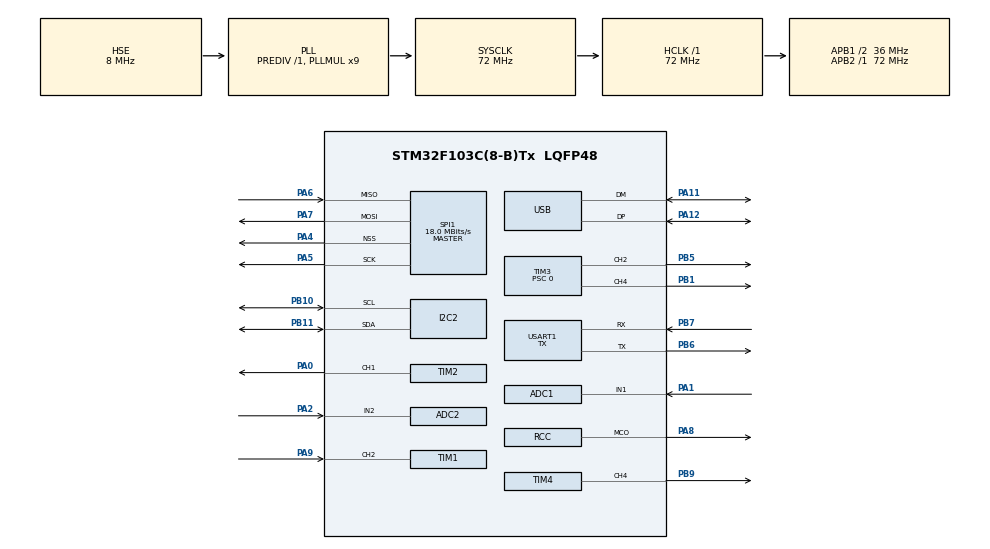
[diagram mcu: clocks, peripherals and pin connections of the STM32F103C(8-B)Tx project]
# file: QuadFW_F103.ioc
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ADC1.Channel-24\#ChannelRegularConversion=ADC_CHANNEL_1
ADC1.NbrOfConversionFlag=1
ADC1.Rank-24\#ChannelRegularConversion=1
ADC1.SamplingTime-24\#ChannelRegularConversion=ADC_SAMPLETIME_1CYCLE_5
ADC1.master=1
ADC2.Channel-18\#ChannelRegularConversion=ADC_CHANNEL_2
ADC2.NbrOfConversionFlag=1
ADC2.Rank-18\#ChannelRegularConversion=1
ADC2.SamplingTime-18\#ChannelRegularConversion=ADC_SAMPLETIME_1CYCLE_5
Dma.Request0=USART1_TX
Dma.USART1_TX.0.Direction=DMA_MEMORY_TO_PERIPH
Dma.USART1_TX.0.Instance=DMA1_Channel4
Dma.USART1_TX.0.MemDataAlignment=DMA_MDATAALIGN_BYTE
Dma.USART1_TX.0.MemInc=DMA_MINC_ENABLE
Dma.USART1_TX.0.Mode=DMA_NORMAL
Dma.USART1_TX.0.PeriphDataAlignment=DMA_PDATAALIGN_BYTE
Dma.USART1_TX.0.PeriphInc=DMA_PINC_DISABLE
Dma.USART1_TX.0.Priority=DMA_PRIORITY_LOW
FREERTOS.BinarySemaphores01=loggerLock,Dynamic,NULL
FREERTOS.INCLUDE_uxTaskPriorityGet=0
FREERTOS.INCLUDE_vTaskDelete=0
FREERTOS.INCLUDE_vTaskPrioritySet=0
FREERTOS.INCLUDE_vTaskSuspend=0
FREERTOS.INCLUDE_xTaskResumeFromISR=0
FREERTOS.Tasks01=systemLoggerTask,-1,512,SystemLoggerTask,As weak,NULL,Dynamic,NULL,NULL;systemCoreTask,3,128,SystemCoreTask,As external,NULL,Dynamic,NULL,NULL
FREERTOS.Timers01=controlTimer,ControlEvent,osTimerPeriodic,As external,NULL,Dynamic,NULL;positionUpdateTimer,PositionUpdateEvent,osTimerPeriodic,As external,NULL,Dynamic,NULL;sendLogTimer,SendLogEvent,osTimerPeriodic,As external,NULL,Dynamic,NULL
FREERTOS.configCHECK_FOR_STACK_OVERFLOW=2
FREERTOS.configGENERATE_RUN_TIME_STATS=0
FREERTOS.configMAX_TASK_NAME_LEN=32
FREERTOS.configMINIMAL_STACK_SIZE=128
FREERTOS.configTIMER_QUEUE_LENGTH=20
FREERTOS.configTIMER_TASK_PRIORITY=6
FREERTOS.configTOTAL_HEAP_SIZE=10240
FREERTOS.configUSE_DAEMON_TASK_STARTUP_HOOK=1
FREERTOS.configUSE_TIMERS=1
FREERTOS.configUSE_TRACE_FACILITY=1
I2C2.I2C_Mode=I2C_Fast
Mcu.Family=STM32F1
Mcu.Name=STM32F103C(8-B)Tx
Mcu.Package=LQFP48
NVIC.DMA1_Channel4_IRQn=true\:5\:0\:false\:false\:true\:true\:false
NVIC.PriorityGroup=NVIC_PRIORITYGROUP_4
NVIC.TIM1_BRK_IRQn=true\:5\:0\:false\:false\:true\:true\:true
NVIC.TIM1_CC_IRQn=true\:5\:0\:false\:false\:true\:true\:true
NVIC.TIM1_TRG_COM_IRQn=true\:5\:0\:false\:false\:true\:true\:true
NVIC.TIM1_UP_IRQn=true\:5\:0\:false\:false\:true\:true\:true
NVIC.USART1_IRQn=true\:5\:0\:false\:false\:true\:true\:true
PA0-WKUP.Signal=S_TIM2_CH1_ETR
PA1.Signal=ADCx_IN1
PA11.Mode=Device
PA11.Signal=USB_DM
PA12.Mode=Device
PA12.Signal=USB_DP
PA13.Mode=Serial_Wire
PA13.Signal=SYS_JTMS-SWDIO
PA14.Mode=Serial_Wire
PA14.Signal=SYS_JTCK-SWCLK
PA2.Signal=ADCx_IN2
PA4.Mode=NSS_Signal_Hard_Output
PA4.Signal=SPI1_NSS
PA5.Mode=Full_Duplex_Master
PA5.Signal=SPI1_SCK
PA6.Mode=Full_Duplex_Master
PA6.Signal=SPI1_MISO
PA7.Mode=Full_Duplex_Master
PA7.Signal=SPI1_MOSI
PA8.Mode=Clock-out
PA8.Signal=RCC_MCO
PA9.Signal=S_TIM1_CH2
PB1.Signal=S_TIM3_CH4
PB10.Mode=I2C
PB10.Signal=I2C2_SCL
PB11.Mode=I2C
PB11.Signal=I2C2_SDA
PB5.Signal=S_TIM3_CH2
PB6.Mode=Asynchronous
PB6.Signal=USART1_TX
PB7.Mode=Asynchronous
PB7.Signal=USART1_RX
PB9.Signal=S_TIM4_CH4
PD0-OSC_IN.Mode=HSE-External-Oscillator
PD0-OSC_IN.Signal=RCC_OSC_IN
PD1-OSC_OUT.Mode=HSE-External-Oscillator
PD1-OSC_OUT.Signal=RCC_OSC_OUT
ProjectManager.HeapSize=0x200
ProjectManager.StackSize=0x400
ProjectManager.TargetToolchain=TrueSTUDIO
RCC.ADCPresc=RCC_ADCPCLK2_DIV6
RCC.AHBFreq_Value=72000000
RCC.APB1CLKDivider=RCC_HCLK_DIV2
RCC.APB1Freq_Value=36000000
RCC.APB1TimFreq_Value=72000000
RCC.APB2Freq_Value=72000000
RCC.APB2TimFreq_Value=72000000
RCC.HCLKFreq_Value=72000000
RCC.PLLMUL=RCC_PLL_MUL9
RCC.RCC_MCOSource=RCC_MCO1SOURCE_PLLCLK
RCC.SYSCLKFreq_VALUE=72000000
RCC.SYSCLKSource=RCC_SYSCLKSOURCE_PLLCLK
RCC.USBFreq_Value=48000000
RCC.USBPrescaler=RCC_USBCLKSOURCE_PLL_DIV1_5
SH.ADCx_IN1.0=ADC1_IN1,IN1
SH.ADCx_IN2.0=ADC2_IN2,IN2
SH.S_TIM1_CH2.0=TIM1_CH2,Input_Capture2_from_TI2
SH.S_TIM2_CH1_ETR.0=TIM2_CH1,PWM Generation1 CH1
SH.S_TIM3_CH2.0=TIM3_CH2,PWM Generation2 CH2
SH.S_TIM3_CH4.0=TIM3_CH4,PWM Generation4 CH4
SH.S_TIM4_CH4.0=TIM4_CH4,PWM Generation4 CH4
SPI1.BaudRatePrescaler=SPI_BAUDRATEPRESCALER_4
SPI1.CalculateBaudRate=18.0 MBits/s
SPI1.Direction=SPI_DIRECTION_2LINES
SPI1.Mode=SPI_MODE_MASTER
SPI1.VirtualNSS=VM_NSSHARD
SPI1.VirtualType=VM_MASTER
TIM1.Channel-Input_Capture2_from_TI2=TIM_CHANNEL_2
TIM1.Period=20000
TIM1.Prescaler=71
TIM2.Channel-PWM\ Generation1\ CH1=TIM_CHANNEL_1
TIM2.Period=1023
TIM2.Prescaler=0
TIM3.Channel-PWM\ Generation2\ CH2=TIM_CHANNEL_2
TIM3.Channel-PWM\ Generation4\ CH4=TIM_CHANNEL_4
TIM3.Period=1023
TIM3.Prescaler=0
TIM4.Channel-PWM\ Generation4\ CH4=TIM_CHANNEL_4
TIM4.Period=1023
TIM4.Prescaler=0
USART1.Mode=MODE_TX
USART1.VirtualMode=VM_ASYNC
VP_FREERTOS_VS_ENABLE.Mode=Enabled
board=custom

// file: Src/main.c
/* USER CODE BEGIN Header */
/**
  ******************************************************************************
  * @file           : main.c
  * @brief          : Main program body
  ******************************************************************************
  * This notice applies to any and all portions of this file
  * that are not between comment pairs USER CODE BEGIN and
  * USER CODE END. Other portions of this file, whether
  * inserted by the user or by software development tools
  * are owned by their respective copyright owners.
  *
  * Copyright (c) 2019 STMicroelectronics International N.V.
  * All rights reserved.
  *
  * Redistribution and use in source and binary forms, with or without
  * modification, are permitted, provided that the following conditions are met:
  *
  * 1. Redistribution of source code must retain the above copyright notice,
  *    this list of conditions and the following disclaimer.
  * 2. Redistributions in binary form must reproduce the above copyright notice,
  *    this list of conditions and the following disclaimer in the documentation
  *    and/or other materials provided with the distribution.
  * 3. Neither the name of STMicroelectronics nor the names of other
  *    contributors to this software may be used to endorse or promote products
  *    derived from this software without specific written permission.
  * 4. This software, including modifications and/or derivative works of this
  *    software, must execute solely and exclusively on microcontroller or
  *    microprocessor devices manufactured by or for STMicroelectronics.
  * 5. Redistribution and use of this software other than as permitted under
  *    this license is void and will automatically terminate your rights under
  *    this license.
  *
  * THIS SOFTWARE IS PROVIDED BY STMICROELECTRONICS AND CONTRIBUTORS "AS IS"
  * AND ANY EXPRESS, IMPLIED OR STATUTORY WARRANTIES, INCLUDING, BUT NOT
  * LIMITED TO, THE IMPLIED WARRANTIES OF MERCHANTABILITY, FITNESS FOR A
  * PARTICULAR PURPOSE AND NON-INFRINGEMENT OF THIRD PARTY INTELLECTUAL PROPERTY
  * RIGHTS ARE DISCLAIMED TO THE FULLEST EXTENT PERMITTED BY LAW. IN NO EVENT
  * SHALL STMICROELECTRONICS OR CONTRIBUTORS BE LIABLE FOR ANY DIRECT, INDIRECT,
  * INCIDENTAL, SPECIAL, EXEMPLARY, OR CONSEQUENTIAL DAMAGES (INCLUDING, BUT NOT
  * LIMITED TO, PROCUREMENT OF SUBSTITUTE GOODS OR SERVICES; LOSS OF USE, DATA,
  * OR PROFITS; OR BUSINESS INTERRUPTION) HOWEVER CAUSED AND ON ANY THEORY OF
  * LIABILITY, WHETHER IN CONTRACT, STRICT LIABILITY, OR TORT (INCLUDING
  * NEGLIGENCE OR OTHERWISE) ARISING IN ANY WAY OUT OF THE USE OF THIS SOFTWARE,
  * EVEN IF ADVISED OF THE POSSIBILITY OF SUCH DAMAGE.
  *
  ******************************************************************************
  */
/* USER CODE END Header */

#include "main.h"
#include "cmsis_os.h"
#include "adc.h"
#include "dma.h"
#include "i2c.h"
#include "spi.h"
#include "tim.h"
#include "usart.h"
#include "usb.h"
#include "gpio.h"

void SystemClock_Config(void);
void MX_FREERTOS_Init(void);

int main(void)
{

  /* MCU Configuration--------------------------------------------------------*/

  /* Reset of all peripherals, Initializes the Flash interface and the Systick. */
  HAL_Init();

  /* Configure the system clock */
  SystemClock_Config();

  /* Initialize all configured peripherals */
  MX_GPIO_Init();
  MX_DMA_Init();
  MX_ADC1_Init();
  MX_TIM2_Init();
  MX_TIM3_Init();
  MX_TIM4_Init();
  MX_USB_PCD_Init();
  MX_I2C2_Init();
  MX_ADC2_Init();
  MX_SPI1_Init();
  MX_TIM1_Init();
  MX_USART1_UART_Init();
  /* USER CODE BEGIN 2 */
  initBsp();
  /* USER CODE END 2 */

  /* Call init function for freertos objects (in freertos.c) */
  MX_FREERTOS_Init();

  /* Start scheduler */
  osKernelStart();

  /* We should never get here as control is now taken by the scheduler */

  /* Infinite loop */
  while (1)
  {

  }
}

void SystemClock_Config(void)
{
  RCC_OscInitTypeDef RCC_OscInitStruct = {0};
  RCC_ClkInitTypeDef RCC_ClkInitStruct = {0};
  RCC_PeriphCLKInitTypeDef PeriphClkInit = {0};

  /**Initializes the CPU, AHB and APB busses clocks
  */
  RCC_OscInitStruct.OscillatorType = RCC_OSCILLATORTYPE_HSE;
  RCC_OscInitStruct.HSEState = RCC_HSE_ON;
  RCC_OscInitStruct.HSEPredivValue = RCC_HSE_PREDIV_DIV1;
  RCC_OscInitStruct.HSIState = RCC_HSI_ON;
  RCC_OscInitStruct.PLL.PLLState = RCC_PLL_ON;
  RCC_OscInitStruct.PLL.PLLSource = RCC_PLLSOURCE_HSE;
  RCC_OscInitStruct.PLL.PLLMUL = RCC_PLL_MUL9;
  if (HAL_RCC_OscConfig(&RCC_OscInitStruct) != HAL_OK)
  {
    Error_Handler();
  }
  /**Initializes the CPU, AHB and APB busses clocks
  */
  RCC_ClkInitStruct.ClockType = RCC_CLOCKTYPE_HCLK|RCC_CLOCKTYPE_SYSCLK
                              |RCC_CLOCKTYPE_PCLK1|RCC_CLOCKTYPE_PCLK2;
  RCC_ClkInitStruct.SYSCLKSource = RCC_SYSCLKSOURCE_PLLCLK;
  RCC_ClkInitStruct.AHBCLKDivider = RCC_SYSCLK_DIV1;
  RCC_ClkInitStruct.APB1CLKDivider = RCC_HCLK_DIV2;
  RCC_ClkInitStruct.APB2CLKDivider = RCC_HCLK_DIV1;

  if (HAL_RCC_ClockConfig(&RCC_ClkInitStruct, FLASH_LATENCY_2) != HAL_OK)
  {
    Error_Handler();
  }
  PeriphClkInit.PeriphClockSelection = RCC_PERIPHCLK_ADC|RCC_PERIPHCLK_USB;
  PeriphClkInit.AdcClockSelection = RCC_ADCPCLK2_DIV6;
  PeriphClkInit.UsbClockSelection = RCC_USBCLKSOURCE_PLL_DIV1_5;
  if (HAL_RCCEx_PeriphCLKConfig(&PeriphClkInit) != HAL_OK)
  {
    Error_Handler();
  }
  HAL_RCC_MCOConfig(RCC_MCO, RCC_MCO1SOURCE_PLLCLK, RCC_MCODIV_1);
}

/* USER CODE BEGIN 4 */
void MX_RESET_I2C(){
	HAL_I2C_DeInit(&hi2c2);
	MX_I2C2_Init();
}
/* USER CODE END 4 */

void Error_Handler(void)
{
}

/************************ (C) COPYRIGHT STMicroelectronics *****END OF FILE****/

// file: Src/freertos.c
/* USER CODE BEGIN Header */
/**
  ******************************************************************************
  * File Name          : freertos.c
  * Description        : Code for freertos applications
  ******************************************************************************
  * This notice applies to any and all portions of this file
  * that are not between comment pairs USER CODE BEGIN and
  * USER CODE END. Other portions of this file, whether
  * inserted by the user or by software development tools
  * are owned by their respective copyright owners.
  *
  * Copyright (c) 2019 STMicroelectronics International N.V.
  * All rights reserved.
  *
  * Redistribution and use in source and binary forms, with or without
  * modification, are permitted, provided that the following conditions are met:
  *
  * 1. Redistribution of source code must retain the above copyright notice,
  *    this list of conditions and the following disclaimer.
  * 2. Redistributions in binary form must reproduce the above copyright notice,
  *    this list of conditions and the following disclaimer in the documentation
  *    and/or other materials provided with the distribution.
  * 3. Neither the name of STMicroelectronics nor the names of other
  *    contributors to this software may be used to endorse or promote products
  *    derived from this software without specific written permission.
  * 4. This software, including modifications and/or derivative works of this
  *    software, must execute solely and exclusively on microcontroller or
  *    microprocessor devices manufactured by or for STMicroelectronics.
  * 5. Redistribution and use of this software other than as permitted under
  *    this license is void and will automatically terminate your rights under
  *    this license.
  *
  * THIS SOFTWARE IS PROVIDED BY STMICROELECTRONICS AND CONTRIBUTORS "AS IS"
  * AND ANY EXPRESS, IMPLIED OR STATUTORY WARRANTIES, INCLUDING, BUT NOT
  * LIMITED TO, THE IMPLIED WARRANTIES OF MERCHANTABILITY, FITNESS FOR A
  * PARTICULAR PURPOSE AND NON-INFRINGEMENT OF THIRD PARTY INTELLECTUAL PROPERTY
  * RIGHTS ARE DISCLAIMED TO THE FULLEST EXTENT PERMITTED BY LAW. IN NO EVENT
  * SHALL STMICROELECTRONICS OR CONTRIBUTORS BE LIABLE FOR ANY DIRECT, INDIRECT,
  * INCIDENTAL, SPECIAL, EXEMPLARY, OR CONSEQUENTIAL DAMAGES (INCLUDING, BUT NOT
  * LIMITED TO, PROCUREMENT OF SUBSTITUTE GOODS OR SERVICES; LOSS OF USE, DATA,
  * OR PROFITS; OR BUSINESS INTERRUPTION) HOWEVER CAUSED AND ON ANY THEORY OF
  * LIABILITY, WHETHER IN CONTRACT, STRICT LIABILITY, OR TORT (INCLUDING
  * NEGLIGENCE OR OTHERWISE) ARISING IN ANY WAY OUT OF THE USE OF THIS SOFTWARE,
  * EVEN IF ADVISED OF THE POSSIBILITY OF SUCH DAMAGE.
  *
  ******************************************************************************
  */
/* USER CODE END Header */

#include "FreeRTOS.h"
#include "task.h"
#include "main.h"

/* USER CODE BEGIN Includes */
#include "core/init.h"
/* USER CODE END Includes */

/* Hook prototypes */
void vApplicationStackOverflowHook(xTaskHandle xTask, signed char *pcTaskName);
void vApplicationDaemonTaskStartupHook(void);

/* USER CODE BEGIN 4 */
__weak void vApplicationStackOverflowHook(xTaskHandle xTask, signed char *pcTaskName)
{
	while(1){}
   /* Run time stack overflow checking is performed if
   configCHECK_FOR_STACK_OVERFLOW is defined to 1 or 2. This hook function is
   called if a stack overflow is detected. */
}
/* USER CODE END 4 */

/* USER CODE BEGIN DAEMON_TASK_STARTUP_HOOK */
void vApplicationDaemonTaskStartupHook(void)
{
	initCore();
}
/* USER CODE END DAEMON_TASK_STARTUP_HOOK */

/************************ (C) COPYRIGHT STMicroelectronics *****END OF FILE****/
